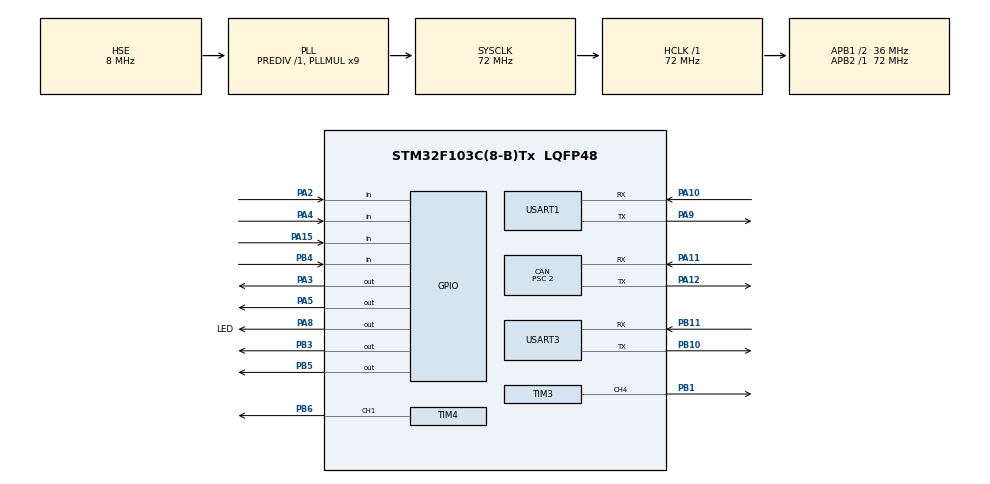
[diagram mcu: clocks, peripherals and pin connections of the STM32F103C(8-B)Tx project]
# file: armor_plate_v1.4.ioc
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CAN.BS1=CAN_BS1_15TQ
CAN.BS2=CAN_BS2_2TQ
CAN.CalculateBaudRate=1000000
CAN.CalculateTimeBit=1000
CAN.CalculateTimeQuantum=55.55555555555556
CAN.Prescaler=2
Dma.Request0=TIM4_CH1
Dma.Request1=TIM3_CH4/UP
Dma.TIM3_CH4/UP.1.Direction=DMA_MEMORY_TO_PERIPH
Dma.TIM3_CH4/UP.1.Instance=DMA1_Channel3
Dma.TIM3_CH4/UP.1.MemDataAlignment=DMA_MDATAALIGN_HALFWORD
Dma.TIM3_CH4/UP.1.MemInc=DMA_MINC_ENABLE
Dma.TIM3_CH4/UP.1.Mode=DMA_NORMAL
Dma.TIM3_CH4/UP.1.PeriphDataAlignment=DMA_PDATAALIGN_HALFWORD
Dma.TIM3_CH4/UP.1.PeriphInc=DMA_PINC_DISABLE
Dma.TIM3_CH4/UP.1.Priority=DMA_PRIORITY_HIGH
Dma.TIM4_CH1.0.Direction=DMA_MEMORY_TO_PERIPH
Dma.TIM4_CH1.0.Instance=DMA1_Channel1
Dma.TIM4_CH1.0.MemDataAlignment=DMA_MDATAALIGN_HALFWORD
Dma.TIM4_CH1.0.MemInc=DMA_MINC_ENABLE
Dma.TIM4_CH1.0.Mode=DMA_NORMAL
Dma.TIM4_CH1.0.PeriphDataAlignment=DMA_PDATAALIGN_HALFWORD
Dma.TIM4_CH1.0.PeriphInc=DMA_PINC_DISABLE
Dma.TIM4_CH1.0.Priority=DMA_PRIORITY_HIGH
FREERTOS.Tasks01=SK6812,2,128,SK6812_LEDS_Task,Default,NULL,Dynamic,NULL,NULL;HX711,3,128,HX711_Task,Default,NULL,Dynamic,NULL,NULL;User,3,128,User_Task,Default,NULL,Dynamic,NULL,NULL;COMM,1,128,Comm_Task,Default,NULL,Dynamic,NULL,NULL
FREERTOS.configUSE_TIMERS=0
Mcu.Family=STM32F1
Mcu.Name=STM32F103C(8-B)Tx
Mcu.Package=LQFP48
NVIC.CAN1_RX1_IRQn=true\:5\:0\:true\:false\:true\:true\:true\:true\:true
NVIC.DMA1_Channel1_IRQn=true\:5\:0\:false\:false\:true\:true\:false\:true\:true
NVIC.DMA1_Channel3_IRQn=true\:5\:0\:false\:false\:true\:true\:false\:true\:true
NVIC.PriorityGroup=NVIC_PRIORITYGROUP_4
NVIC.TIM2_IRQn=true\:15\:0\:false\:false\:true\:false\:false\:true\:true
NVIC.TimeBase=TIM2_IRQn
NVIC.TimeBaseIP=TIM2
PA10.Mode=Asynchronous
PA10.Signal=USART1_RX
PA11.Mode=CAN_Activate
PA11.Signal=CAN_RX
PA12.Mode=CAN_Activate
PA12.Signal=CAN_TX
PA13.Mode=Serial_Wire
PA13.Signal=SYS_JTMS-SWDIO
PA14.Mode=Serial_Wire
PA14.Signal=SYS_JTCK-SWCLK
PA15.Signal=GPIO_Input
PA2.Signal=GPIO_Input
PA3.GPIO_Speed=GPIO_SPEED_FREQ_LOW
PA3.Signal=GPIO_Output
PA4.Signal=GPIO_Input
PA5.GPIO_Speed=GPIO_SPEED_FREQ_LOW
PA5.Signal=GPIO_Output
PA8.GPIO_Label=LED
PA8.GPIO_Speed=GPIO_SPEED_FREQ_LOW
PA8.PinState=GPIO_PIN_RESET
PA8.Signal=GPIO_Output
PA9.Mode=Asynchronous
PA9.Signal=USART1_TX
PB1.Signal=S_TIM3_CH4
PB10.Mode=Asynchronous
PB10.Signal=USART3_TX
PB11.Mode=Asynchronous
PB11.Signal=USART3_RX
PB3.GPIO_Speed=GPIO_SPEED_FREQ_LOW
PB3.Signal=GPIO_Output
PB4.Signal=GPIO_Input
PB5.GPIO_Speed=GPIO_SPEED_FREQ_LOW
PB5.Signal=GPIO_Output
PB6.Signal=S_TIM4_CH1
PD0-OSC_IN.Mode=HSE-External-Oscillator
PD0-OSC_IN.Signal=RCC_OSC_IN
PD1-OSC_OUT.Mode=HSE-External-Oscillator
PD1-OSC_OUT.Signal=RCC_OSC_OUT
ProjectManager.HeapSize=0x200
ProjectManager.StackSize=0x400
ProjectManager.TargetToolchain=MDK-ARM V5.32
RCC.AHBFreq_Value=72000000
RCC.APB1CLKDivider=RCC_HCLK_DIV2
RCC.APB1Freq_Value=36000000
RCC.APB1TimFreq_Value=72000000
RCC.APB2Freq_Value=72000000
RCC.APB2TimFreq_Value=72000000
RCC.HCLKFreq_Value=72000000
RCC.PLLMUL=RCC_PLL_MUL9
RCC.PLLSourceVirtual=RCC_PLLSOURCE_HSE
RCC.SYSCLKFreq_VALUE=72000000
RCC.SYSCLKSource=RCC_SYSCLKSOURCE_PLLCLK
RCC.USBFreq_Value=72000000
SH.S_TIM3_CH4.0=TIM3_CH4,PWM Generation4 CH4
SH.S_TIM4_CH1.0=TIM4_CH1,PWM Generation1 CH1
TIM1.Period=65535
TIM1.Prescaler=9-1
TIM3.Channel-PWM\ Generation4\ CH4=TIM_CHANNEL_4
TIM3.Period=89
TIM4.Channel-PWM\ Generation1\ CH1=TIM_CHANNEL_1
TIM4.Period=89
USART1.VirtualMode=VM_ASYNC
USART3.VirtualMode=VM_ASYNC
VP_FREERTOS_VS_CMSIS_V1.Mode=CMSIS_V1
VP_SYS_VS_tim2.Mode=TIM2
VP_TIM1_VS_ClockSourceINT.Mode=Internal
VP_TIM3_VS_ClockSourceINT.Mode=Internal
VP_TIM4_VS_ClockSourceINT.Mode=Internal
board=custom

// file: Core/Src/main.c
/* USER CODE BEGIN Header */
/**
  ******************************************************************************
  * @file           : main.c
  * @brief          : Main program body
  ******************************************************************************
  * @attention
  *
  * Copyright (c) 2023 STMicroelectronics.
  * All rights reserved.
  *
  * This software is licensed under terms that can be found in the LICENSE file
  * in the root directory of this software component.
  * If no LICENSE file comes with this software, it is provided AS-IS.
  *
  ******************************************************************************
  */
/* USER CODE END Header */
#include "main.h"
#include "cmsis_os.h"
#include "can.h"
#include "dma.h"
#include "tim.h"
#include "usart.h"
#include "gpio.h"

/* USER CODE BEGIN Includes */

#include "sk6812.h"
#include "hx711.h"

/* USER CODE END Includes */

void SystemClock_Config(void);
void MX_FREERTOS_Init(void);

int main(void)
{

  /* MCU Configuration--------------------------------------------------------*/

  /* Reset of all peripherals, Initializes the Flash interface and the Systick. */
  HAL_Init();

  /* Configure the system clock */
  SystemClock_Config();

  /* Initialize all configured peripherals */
  MX_GPIO_Init();
  MX_DMA_Init();
  MX_TIM3_Init();
  MX_TIM4_Init();
  MX_CAN_Init();
  MX_USART1_UART_Init();
  MX_USART3_UART_Init();
  MX_TIM1_Init();

  /* Call init function for freertos objects (in freertos.c) */
  MX_FREERTOS_Init();

  /* Start scheduler */
  osKernelStart();

  /* We should never get here as control is now taken by the scheduler */
  /* Infinite loop */
  while (1)
  {

  }
}

void SystemClock_Config(void)
{
  RCC_OscInitTypeDef RCC_OscInitStruct = {0};
  RCC_ClkInitTypeDef RCC_ClkInitStruct = {0};

  /** Initializes the RCC Oscillators according to the specified parameters
  * in the RCC_OscInitTypeDef structure.
  */
  RCC_OscInitStruct.OscillatorType = RCC_OSCILLATORTYPE_HSE;
  RCC_OscInitStruct.HSEState = RCC_HSE_ON;
  RCC_OscInitStruct.HSEPredivValue = RCC_HSE_PREDIV_DIV1;
  RCC_OscInitStruct.HSIState = RCC_HSI_ON;
  RCC_OscInitStruct.PLL.PLLState = RCC_PLL_ON;
  RCC_OscInitStruct.PLL.PLLSource = RCC_PLLSOURCE_HSE;
  RCC_OscInitStruct.PLL.PLLMUL = RCC_PLL_MUL9;
  if (HAL_RCC_OscConfig(&RCC_OscInitStruct) != HAL_OK)
  {
    Error_Handler();
  }

  /** Initializes the CPU, AHB and APB buses clocks
  */
  RCC_ClkInitStruct.ClockType = RCC_CLOCKTYPE_HCLK|RCC_CLOCKTYPE_SYSCLK
                              |RCC_CLOCKTYPE_PCLK1|RCC_CLOCKTYPE_PCLK2;
  RCC_ClkInitStruct.SYSCLKSource = RCC_SYSCLKSOURCE_PLLCLK;
  RCC_ClkInitStruct.AHBCLKDivider = RCC_SYSCLK_DIV1;
  RCC_ClkInitStruct.APB1CLKDivider = RCC_HCLK_DIV2;
  RCC_ClkInitStruct.APB2CLKDivider = RCC_HCLK_DIV1;

  if (HAL_RCC_ClockConfig(&RCC_ClkInitStruct, FLASH_LATENCY_2) != HAL_OK)
  {
    Error_Handler();
  }
}

void HAL_TIM_PeriodElapsedCallback(TIM_HandleTypeDef *htim)
{
  if (htim->Instance == TIM2) {
    HAL_IncTick();
  }
}

void Error_Handler(void)
{
  __disable_irq();
  while (1)
  {
  }
}

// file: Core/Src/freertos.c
/* USER CODE BEGIN Header */
/**
  ******************************************************************************
  * File Name          : freertos.c
  * Description        : Code for freertos applications
  ******************************************************************************
  * @attention
  *
  * Copyright (c) 2023 STMicroelectronics.
  * All rights reserved.
  *
  * This software is licensed under terms that can be found in the LICENSE file
  * in the root directory of this software component.
  * If no LICENSE file comes with this software, it is provided AS-IS.
  *
  ******************************************************************************
  */
/* USER CODE END Header */

#include "FreeRTOS.h"
#include "task.h"
#include "main.h"
#include "cmsis_os.h"

osThreadId SK6812Handle;
osThreadId HX711Handle;
osThreadId UserHandle;
osThreadId COMMHandle;

void SK6812_LEDS_Task(void const * argument);
void HX711_Task(void const * argument);
void User_Task(void const * argument);
void Comm_Task(void const * argument);

void MX_FREERTOS_Init(void); /* (MISRA C 2004 rule 8.1) */

/* GetIdleTaskMemory prototype (linked to static allocation support) */
void vApplicationGetIdleTaskMemory( StaticTask_t **ppxIdleTaskTCBBuffer, StackType_t **ppxIdleTaskStackBuffer, uint32_t *pulIdleTaskStackSize );

/* USER CODE BEGIN GET_IDLE_TASK_MEMORY */
static StaticTask_t xIdleTaskTCBBuffer;
static StackType_t xIdleStack[configMINIMAL_STACK_SIZE];

void vApplicationGetIdleTaskMemory( StaticTask_t **ppxIdleTaskTCBBuffer, StackType_t **ppxIdleTaskStackBuffer, uint32_t *pulIdleTaskStackSize )
{
  *ppxIdleTaskTCBBuffer = &xIdleTaskTCBBuffer;
  *ppxIdleTaskStackBuffer = &xIdleStack[0];
  *pulIdleTaskStackSize = configMINIMAL_STACK_SIZE;
  /* place for user code */
}
/* USER CODE END GET_IDLE_TASK_MEMORY */

void MX_FREERTOS_Init(void) {

  /* Create the thread(s) */
  /* definition and creation of SK6812 */
  osThreadDef(SK6812, SK6812_LEDS_Task, osPriorityHigh, 0, 128);
  SK6812Handle = osThreadCreate(osThread(SK6812), NULL);

  /* definition and creation of HX711 */
  osThreadDef(HX711, HX711_Task, osPriorityRealtime, 0, 128);
  HX711Handle = osThreadCreate(osThread(HX711), NULL);

  /* definition and creation of User */
  osThreadDef(User, User_Task, osPriorityRealtime, 0, 128);
  UserHandle = osThreadCreate(osThread(User), NULL);

  /* definition and creation of COMM */
  osThreadDef(COMM, Comm_Task, osPriorityAboveNormal, 0, 128);
  COMMHandle = osThreadCreate(osThread(COMM), NULL);

}
